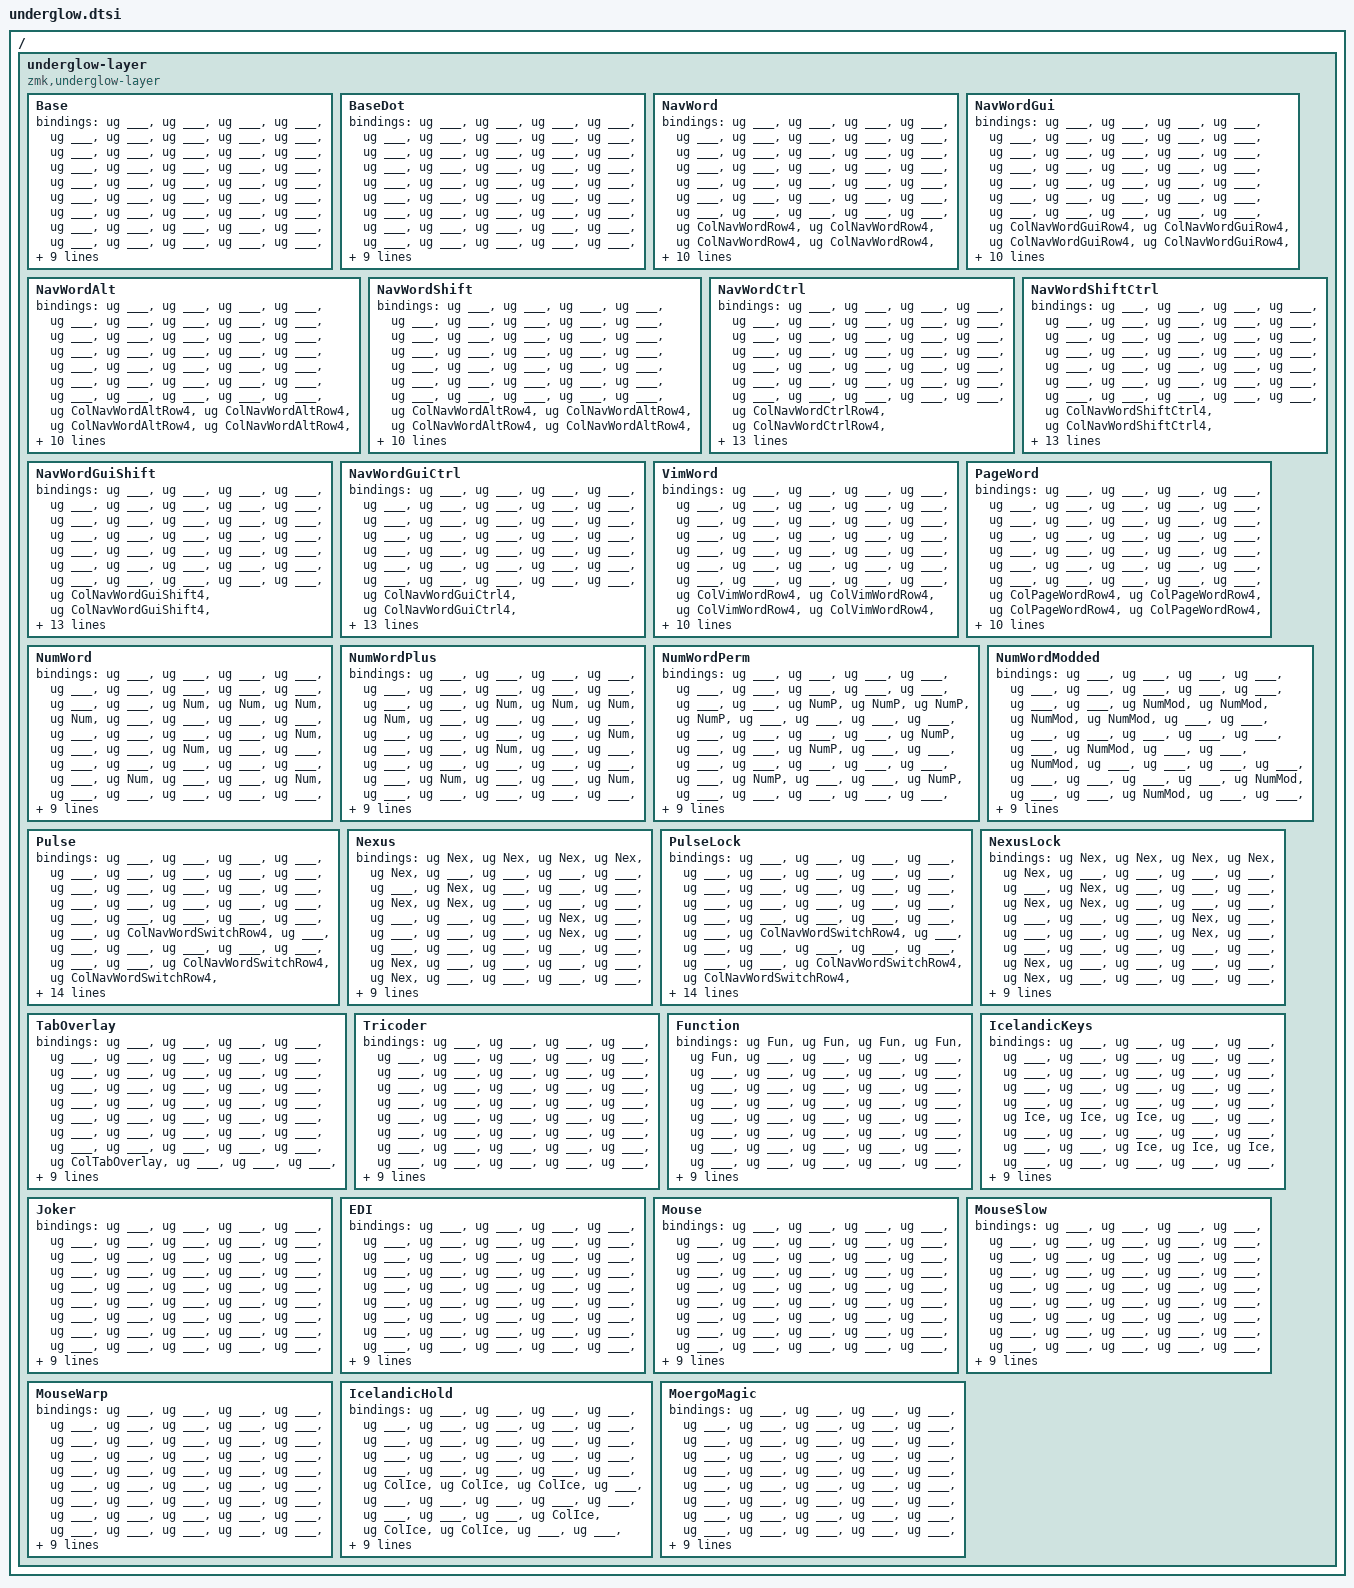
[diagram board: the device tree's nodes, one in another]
/ {
	#define GREEN 0x00ff00
	#define RED 0xff0000
	#define BLUE 0x0000ff
	#define TEAL 0x008080
	#define ORANGE 0xffa500
	#define YELLOW 0xffff00
	#define GOLD 0xffd700
	#define PURPLE 0x800080
	#define PINK 0xffc0cb
	#define WHITE 0xffffff
	#define ___ 0x000000
	
	// Added expanded palette (short names; comments clarify)
	#define CYAN 0x00ffff
	#define MAGENTA 0xff00ff
	#define AMBER 0xffbf00// warm amber
	#define CORAL 0xff7f50
	#define SALMON 0xfa8072
	#define ROSE 0xff007f// rose pink
	#define VIOLET 0xee82ee
	#define INDIGO 0x4b0082
	#define LAVENDER 0xe6e6fa
	#define SKY 0x87ceeb// sky blue
	#define DODGER 0x1e90ff// dodger blue
	#define NAVY 0x000080
	#define MAROON 0x800000
	#define OLIVE 0x808000
	#define BROWN 0x8b4513
	#define MINT 0x98ff98
	#define TURQ 0x40e0d0// turquoise
	#define CHART 0x7fff00// chartreuse
	#define STEEL 0x4682b4// steel blue
	#define SLATE 0x708090// slate gray
	
	// Semantic layer colors (edit here to change theme)
	#define ColMouse   CYAN
	#define ColSlow    STEEL
	#define ColWarp    MAGENTA
	#define ColFast    DODGER
	
	#define ColCtrl    TEAL
	#define ColAlt     BLUE
	#define ColShift   PINK
	#define ColGui     ORANGE
	
	// Navigation and indicators
	#define ColNav     WHITE
	#define ColLayer   WHITE// binary indicator bits (top-left)
	
	// Per-nav-layer row-4 accents
	#define ColNavWordRow4       0x33ccff
	#define ColNavWordGuiRow4    0xff9966
	#define ColNavWordAltRow4    0xcc99ff
	#define ColNavWordCtrlRow4   0x66ff99
	#define ColNavWordShiftCtrl4 0xff66cc
	#define ColNavWordGuiShift4  0xffcc66
	#define ColNavWordGuiCtrl4   0x99ffcc
	#define ColNavWordSwitchRow4 0x66ccff
	#define ColVimWordRow4       0x5cffb8
	#define ColPageWordRow4      0xff7f5c
	
	// Nexus row-1 accents
	#define Nex       0x5ad1ff
	#define ColNexusOverlayRow1 0xffb347
	#define ColTabOverlay    0x1ec912
	
	// Num row-2 accents (distinct from Nexus palette)
	/* #define Num     0xff4da6 */
	#define Num  0xedb228
	#define NumP  0x3cff9a
	#define NumMod   0x6f7bff
	
	// Mouse row-6 accents (distinct palette)
	#define Mou    0x4de2ff
	#define MouS    0x7dff4d
	#define MouW    0xff6fe0
	#define MouF    0xffe14d
	#define MouSw  0x9c7bff
	
	// Icelandic rows 3/4 accent
	#define Ice 0x3a7eea
	
	// Function row-3 accent (red, distinct from nav/num)
	#define Fun 0xff4444
	
	// Numeric layers
	#define ColNum     WHITE
	#define ColNumMod  GREEN
	#define ColNumPlus GOLD
	
	// Numeric shades (distinct hues per layer)
	// ColNum: vivid but not harsh, varied hues
	#define ColNum1  0x66ccff
	#define ColNum2  0x99aaff
	#define ColNum3  0xff99c2
	#define ColNum4  0x66ffcc
	#define ColNum5  0xffcc66
	#define ColNum6  0x66ffff
	#define ColNum7  0xcc99ff
	#define ColNum8  0xff99e6
	#define ColNum9  0x66ffd9
	#define ColNum0  0x80e5ff
	
	// ColNumMod: green/teal family, brighter tints
	#define ColNumMod1  0x2ee6a6
	#define ColNumMod2  0x00cc99
	#define ColNumMod3  0x66ff66
	#define ColNumMod4  0x99ff33
	#define ColNumMod5  0x00ff99
	#define ColNumMod6  0x33ffcc
	#define ColNumMod7  0x66e6b8
	#define ColNumMod8  0x00e673
	#define ColNumMod9  0x7fff7f
	#define ColNumMod0  0x33d17a
	
	// ColNumPlus: amber/orange family, distinct steps
	#define ColNumPlus1  0xffb84d
	#define ColNumPlus2  0xffc266
	#define ColNumPlus3  0xff9933
	#define ColNumPlus4  0xffd24d
	#define ColNumPlus5  0xffbf00
	#define ColNumPlus6  0xffcc33
	#define ColNumPlus7  0xffa64d
	#define ColNumPlus8  0xff8c1a
	#define ColNumPlus9  0xffb366
	#define ColNumPlus0  0xffa500
	
	// Page/Vim layers
	#define ColVim  WHITE
	#define ColPage WHITE
	
	// Other layers
	#define ColFun  PURPLE// function keys
	#define ColIce  SKY// icelandic layer
	#define ColSym1 AMBER// symbol layer
	#define ColSym2 GOLD// symbol layer
	#define ColSym3 CORAL// symbol layer
	
	/* &ug ___ sets the underglow LED to the specified color.  */
	/* &ug ___ sets the underglow color according to the CAPSLOCK state.  */
	/* &ug_nl and &ug_sl do the same for NumLock & ScrollLock respectively. */
	
	underglow-layer {
		compatible  = "zmk,underglow-layer";
		
		Base {
			bindings = <
			&ug ___ &ug ___ &ug ___   &ug ___   &ug ___                                                                    &ug ___ &ug ___ &ug ___ &ug ___ &ug ___
			&ug ___ &ug ___ &ug ___   &ug ___   &ug ___   &ug ___                                                  &ug ___ &ug ___ &ug ___ &ug ___ &ug ___ &ug ___
			&ug ___ &ug ___ &ug ___   &ug ___   &ug ___   &ug ___                                                  &ug ___ &ug ___ &ug ___ &ug ___ &ug ___ &ug ___
			&ug ___ &ug ___ &ug ___   &ug ___   &ug ___   &ug ___                                                  &ug ___ &ug ___ &ug ___ &ug ___ &ug ___ &ug ___
			&ug ___ &ug ___ &ug ___   &ug ___   &ug ___   &ug ___ &ug ___ &ug ___ &ug ___  &ug ___ &ug ___ &ug ___ &ug ___ &ug ___   &ug ___   &ug ___ &ug ___ &ug ___
			&ug ___ &ug ___ &ug_cl ___ WHITE   &ug ___   &ug ___           &ug ___ &ug ___ &ug ___ &ug ___ &ug ___ &ug ___ &ug ___ &ug ___ &ug ___ &ug ___ &ug ___
			>;
			layer-id = <BASE>;
		};
		
		BaseDot {
			bindings = <
			&ug ___ &ug ___ &ug ___   &ug ___   &ug ___                                                          &ug ___ &ug ___ &ug ___ &ug ___ &ug ___
			&ug ___ &ug ___ &ug ___     &ug ___   &ug ___   &ug ___                                          &ug ___ &ug ___ &ug ___ &ug ___ &ug ___ &ug ___
			&ug ___ &ug ___ &ug ___     &ug ___   &ug ___   &ug ___                                          &ug ___ &ug ___ &ug ___ &ug ___ &ug ___ &ug ___
			&ug ___ &ug ___ &ug ___     &ug ___   &ug ___   &ug ___                                          &ug ___ &ug ___ &ug ___ &ug ___ &ug ___ &ug ___
			&ug ___ &ug ___ &ug ___     &ug ___   &ug ___   &ug ___ &ug ___ &ug ___ &ug ___  &ug ___ &ug ___ &ug ___ &ug ___ &ug ___ &ug ___ &ug ___ &ug ___ &ug ___
			&ug ___ &ug ___ &ug ___     &ug ___   &ug ___           &ug ___ &ug ___ &ug ___ &ug ___ &ug ___ &ug ___ &ug ___ &ug ___ &ug ___ &ug ___ &ug ___
			>;
			layer-id = <BASE_DOT>;
		};

		NavWord {
			bindings = <
			&ug ___  &ug ___  &ug ___    &ug ___  &ug ___                                                                                &ug ___ &ug ___ &ug ___ &ug ___ &ug ___
			&ug ___  &ug ___  &ug ___    &ug ___  &ug ___  &ug ___                                                       &ug ___ &ug ___ &ug ___ &ug ___ &ug ___ &ug ___
			&ug ___  &ug ___  &ug ___    &ug ___  &ug ___  &ug ___                                                       &ug ___ &ug ___ &ug ___ &ug ___ &ug ___ &ug ___
			&ug ColNavWordRow4  &ug ColNavWordRow4  &ug ColNavWordRow4    &ug ColNavWordRow4  &ug ColNavWordRow4  &ug ColNavWordRow4                                                       &ug ___ &ug ___ &ug ___ &ug ___ &ug ___ &ug ___
			&ug ___  &ug ___  &ug ___    &ug ___   &ug ___  &ug ___  &ug ___  &ug ___  &ug ___     &ug ___  &ug ___  &ug ___    &ug ___    &ug ___     &ug ___     &ug ___     &ug ___  &ug ___
			&ug ___  &ug ___  &ug ___    &ug ___  &ug ___          &ug ___ &ug ___ &ug ___ &ug ___ &ug ___ &ug ___ &ug ___ &ug ___ &ug ___ &ug ___ &ug ___
			>;
			layer-id = <NAV_WORD>;
		};
		
		NavWordGui {
			bindings = <
			&ug ___  &ug ___  &ug ___    &ug ___  &ug ___                                                                         &ug ___ &ug ___ &ug ___ &ug ___ &ug ___
			&ug ___  &ug ___  &ug ___    &ug ___  &ug ___  &ug ___                                                              &ug ___ &ug ___ &ug ___ &ug ___ &ug ___ &ug ___
			&ug ___  &ug ___  &ug ___    &ug ___  &ug ___  &ug ___                                                              &ug ___ &ug ___ &ug ___ &ug ___ &ug ___ &ug ___
			&ug ColNavWordGuiRow4  &ug ColNavWordGuiRow4  &ug ColNavWordGuiRow4    &ug ColNavWordGuiRow4  &ug ColNavWordGuiRow4  &ug ColNavWordGuiRow4                                                       &ug ___ &ug ___ &ug ___ &ug ___ &ug ___ &ug ___
			&ug ___  &ug ___  &ug ___    &ug ___   &ug ___  &ug ___  &ug ___         &ug ___ &ug ___ &ug ___ &ug ___ &ug ___ &ug ___ &ug ___ &ug ___ &ug ___ &ug ___
			&ug ___  &ug ___  &ug ___    &ug ___  &ug ___          &ug ___ &ug ___ &ug ___ &ug ___ &ug ___ &ug ___ &ug ___ &ug ___ &ug ___ &ug ___ &ug ___
			>;
			layer-id = <NAV_WORD_GUI>;
		};
		
		NavWordAlt {
			bindings = <
			&ug ___ &ug ___ &ug ___    &ug ___  &ug ___                                                                         &ug ___ &ug ___ &ug ___ &ug ___ &ug ___
			&ug ___ &ug ___  &ug ___   &ug ___   &ug ___   &ug ___                                                 &ug ___ &ug ___ &ug ___ &ug ___ &ug ___ &ug ___
			&ug ___ &ug ___  &ug ___   &ug ___   &ug ___   &ug ___                                                 &ug ___ &ug ___ &ug ___ &ug ___ &ug ___ &ug ___
			&ug ColNavWordAltRow4 &ug ColNavWordAltRow4  &ug ColNavWordAltRow4   &ug ColNavWordAltRow4   &ug ColNavWordAltRow4   &ug ColNavWordAltRow4                                                 &ug ___ &ug ___ &ug ___ &ug ___ &ug ___ &ug ___
			&ug ___ &ug ___  &ug ___   &ug ___   &ug ___   &ug ___ &ug ___ &ug ___ &ug ___  &ug ___ &ug ___ &ug ___ &ug ___ &ug ___  &ug ___   &ug ___ &ug ___ &ug ___
			&ug ___ &ug ___  &ug ___   &ug ___   &ug ___           &ug ___ &ug ___ &ug ___ &ug ___ &ug ___ &ug ___ &ug ___ &ug ___ &ug ___ &ug ___ &ug ___
			>;
			layer-id = <NAV_WORD_ALT>;
		};
		
		NavWordShift {
			bindings = <
			&ug ___ &ug ___ &ug ___    &ug ___  &ug ___                                                                         &ug ___ &ug ___ &ug ___ &ug ___ &ug ___
			&ug ___ &ug ___  &ug ___   &ug ___   &ug ___   &ug ___                                                 &ug ___ &ug ___ &ug ___ &ug ___ &ug ___ &ug ___
			&ug ___ &ug ___  &ug ___   &ug ___   &ug ___   &ug ___                                                 &ug ___ &ug ___ &ug ___ &ug ___ &ug ___ &ug ___
			&ug ColNavWordAltRow4 &ug ColNavWordAltRow4  &ug ColNavWordAltRow4   &ug ColNavWordAltRow4   &ug ColNavWordAltRow4   &ug ColNavWordAltRow4                                                 &ug ___ &ug ___ &ug ___ &ug ___ &ug ___ &ug ___
			&ug ___ &ug ___  &ug ___   &ug ___   &ug ___   &ug ___ &ug ___ &ug ___ &ug ___  &ug ___ &ug ___ &ug ___ &ug ___ &ug ___  &ug ___   &ug ___ &ug ___ &ug ___
			&ug ___ &ug ___  &ug ___   &ug ___   &ug ___           &ug ___ &ug ___ &ug ___ &ug ___ &ug ___ &ug ___ &ug ___ &ug ___ &ug ___ &ug ___ &ug ___
			>;
			layer-id = <NAV_WORD_SHIFT>;
		};
		
		NavWordCtrl {
			bindings = <
			&ug ___  &ug ___  &ug ___    &ug ___  &ug ___                                                                         &ug ___ &ug ___ &ug ___ &ug ___ &ug ___
			&ug ___  &ug ___  &ug ___    &ug ___  &ug ___  &ug ___                                                       &ug ___ &ug ___ &ug ___ &ug ___ &ug ___ &ug ___
			&ug ___  &ug ___  &ug ___    &ug ___  &ug ___  &ug ___                                                       &ug ___ &ug ___ &ug ___ &ug ___ &ug ___ &ug ___
			&ug ColNavWordCtrlRow4  &ug ColNavWordCtrlRow4  &ug ColNavWordCtrlRow4    &ug ColNavWordCtrlRow4  &ug ColNavWordCtrlRow4  &ug ColNavWordCtrlRow4                                                       &ug ___ &ug ___ &ug ___ &ug ___ &ug ___ &ug ___
			&ug ___  &ug ___  &ug ___    &ug ___   &ug ___  &ug ___  &ug ___  &ug ___  &ug ___     &ug ___  &ug ___  &ug ___    &ug ___    &ug ___     &ug ___     &ug ___     &ug ___  &ug ___
			&ug ___  &ug ___  &ug ___    &ug ___  &ug ___          &ug ___ &ug ___ &ug ___ &ug ___ &ug ___ &ug ___ &ug ___ &ug ___ &ug ___ &ug ___ &ug ___
			>;
			layer-id = <NAV_WORD_CTRL>;
		};
		
		NavWordShiftCtrl {
			bindings = <
			&ug ___  &ug ___  &ug ___    &ug ___  &ug ___                                                                                &ug ___ &ug ___ &ug ___ &ug ___ &ug ___
			&ug ___  &ug ___  &ug ___    &ug ___  &ug ___  &ug ___                                                       &ug ___ &ug ___ &ug ___ &ug ___ &ug ___ &ug ___
			&ug ___  &ug ___  &ug ___    &ug ___  &ug ___  &ug ___                                                       &ug ___ &ug ___ &ug ___ &ug ___ &ug ___ &ug ___
			&ug ColNavWordShiftCtrl4  &ug ColNavWordShiftCtrl4  &ug ColNavWordShiftCtrl4    &ug ColNavWordShiftCtrl4  &ug ColNavWordShiftCtrl4  &ug ColNavWordShiftCtrl4                                                       &ug ___ &ug ___ &ug ___ &ug ___ &ug ___ &ug ___
			&ug ___  &ug ___  &ug ___    &ug ___   &ug ___  &ug ___  &ug ___  &ug ___  &ug ___     &ug ___  &ug ___  &ug ___    &ug ___    &ug ___     &ug ___     &ug ___     &ug ___  &ug ___
			&ug ___  &ug ___  &ug ___    &ug ___  &ug ___          &ug ___ &ug ___ &ug ___ &ug ___ &ug ___ &ug ___ &ug ___ &ug ___ &ug ___ &ug ___ &ug ___
			>;
			layer-id = <NAV_WORD_SHIFT_CTRL>;
		};
		
		NavWordGuiShift {
			bindings = <
			&ug ___  &ug ___  &ug ___    &ug ___  &ug ___                                                                         &ug ___ &ug ___ &ug ___ &ug ___ &ug ___
			&ug ___  &ug ___  &ug ___    &ug ___  &ug ___  &ug ___                                                              &ug ___ &ug ___ &ug ___ &ug ___ &ug ___ &ug ___
			&ug ___  &ug ___  &ug ___    &ug ___  &ug ___  &ug ___                                                              &ug ___ &ug ___ &ug ___ &ug ___ &ug ___ &ug ___
			&ug ColNavWordGuiShift4  &ug ColNavWordGuiShift4  &ug ColNavWordGuiShift4    &ug ColNavWordGuiShift4  &ug ColNavWordGuiShift4  &ug ColNavWordGuiShift4                                                       &ug ___ &ug ___ &ug ___ &ug ___ &ug ___ &ug ___
			&ug ___  &ug ___  &ug ___    &ug ___   &ug ___  &ug ___  &ug ___  &ug ___  &ug ___     &ug ___  &ug ___  &ug ___    &ug ___    &ug ___     &ug ___     &ug ___     &ug ___  &ug ___
			&ug ___  &ug ___  &ug ___    &ug ___  &ug ___          &ug ___ &ug ___ &ug ___ &ug ___ &ug ___ &ug ___ &ug ___ &ug ___ &ug ___ &ug ___ &ug ___
			>;
			layer-id = <NAV_WORD_SHIFT_GUI>;
		};
		
		NavWordGuiCtrl {
			bindings = <
			&ug ___  &ug ___  &ug ___    &ug ___  &ug ___                                                                         &ug ___ &ug ___ &ug ___ &ug ___ &ug ___
			&ug ___  &ug ___  &ug ___    &ug ___  &ug ___  &ug ___                                                              &ug ___ &ug ___ &ug ___ &ug ___ &ug ___ &ug ___
			&ug ___  &ug ___  &ug ___    &ug ___  &ug ___  &ug ___                                                              &ug ___ &ug ___ &ug ___ &ug ___ &ug ___ &ug ___
			&ug ColNavWordGuiCtrl4  &ug ColNavWordGuiCtrl4  &ug ColNavWordGuiCtrl4    &ug ColNavWordGuiCtrl4  &ug ColNavWordGuiCtrl4  &ug ColNavWordGuiCtrl4                                                       &ug ___ &ug ___ &ug ___ &ug ___ &ug ___ &ug ___
			&ug ___  &ug ___  &ug ___    &ug ___   &ug ___  &ug ___  &ug ___  &ug ___  &ug ___     &ug ___  &ug ___  &ug ___    &ug ___    &ug ___     &ug ___     &ug ___     &ug ___  &ug ___
			&ug ___  &ug ___  &ug ___    &ug ___  &ug ___          &ug ___ &ug ___ &ug ___ &ug ___ &ug ___ &ug ___ &ug ___ &ug ___ &ug ___ &ug ___ &ug ___
			>;
			layer-id = <NAV_WORD_CTRL_GUI>;
		};
		
		VimWord {
			bindings = <
			&ug ___ &ug ___ &ug ___   &ug ___   &ug ___                                                                &ug ___ &ug ___ &ug ___ &ug ___ &ug ___
			&ug ___  &ug ___ &ug ___   &ug ___     &ug ___   &ug ___                                              &ug ___ &ug ___ &ug ___ &ug ___ &ug ___ &ug ___
			&ug ___  &ug ___ &ug ___   &ug ___     &ug ___   &ug ___                                              &ug ___ &ug ___ &ug ___ &ug ___ &ug ___ &ug ___
			&ug ColVimWordRow4  &ug ColVimWordRow4 &ug ColVimWordRow4   &ug ColVimWordRow4     &ug ColVimWordRow4   &ug ColVimWordRow4                                              &ug ___ &ug ___ &ug ___ &ug ___ &ug ___ &ug ___
			&ug ___  &ug ___ &ug ___   &ug ___     &ug ___   &ug ___ &ug ___ &ug ___ &ug ___  &ug ___ &ug ___ &ug ___ &ug ___ &ug ___ &ug ___   &ug ___ &ug ___ &ug ___
			&ug ___  &ug ___ &ug ___   &ug ___     &ug ___           &ug ___ &ug ___ &ug ___ &ug ___ &ug ___ &ug ___ &ug ___ &ug ___ &ug ___ &ug ___ &ug ___
			>;
			layer-id = <VIM_WORD>;
		};
		
		PageWord {
			bindings = <
			&ug ___ &ug ___ &ug ___   &ug ___   &ug ___                                                                    &ug ___ &ug ___ &ug ___ &ug ___ &ug ___
			&ug ___ &ug ___  &ug ___   &ug ___     &ug ___   &ug ___                                              &ug ___ &ug ___ &ug ___ &ug ___ &ug ___ &ug ___
			&ug ___ &ug ___  &ug ___   &ug ___     &ug ___   &ug ___                                              &ug ___ &ug ___ &ug ___ &ug ___ &ug ___ &ug ___
			&ug ColPageWordRow4 &ug ColPageWordRow4  &ug ColPageWordRow4   &ug ColPageWordRow4     &ug ColPageWordRow4   &ug ColPageWordRow4                                              &ug ___ &ug ___ &ug ___ &ug ___ &ug ___ &ug ___
			&ug ___ &ug ___  &ug ___   &ug ___     &ug ___   &ug ___ &ug ___ &ug ___ &ug ___  &ug ___ &ug ___ &ug ___ &ug ___ &ug ___ &ug ___   &ug ___ &ug ___ &ug ___
			&ug ___ &ug ___  &ug ___   &ug ___     &ug ___           &ug ___ &ug ___ &ug ___ &ug ___ &ug ___ &ug ___ &ug ___ &ug ___ &ug ___ &ug ___ &ug ___
			>;
			layer-id = <PAGE_WORD>;
		};
		
		NumWord {
			bindings = <
			&ug ___ &ug ___ &ug ___ &ug ___ &ug ___                                                              &ug ___ &ug ___ &ug ___ &ug ___ &ug ___
			&ug ___ &ug Num &ug Num &ug Num &ug Num &ug ___                                                  &ug ___ &ug ___ &ug ___ &ug ___ &ug ___ &ug ___
			&ug ___ &ug Num &ug ___ &ug ___ &ug Num &ug ___                                                  &ug ___ &ug ___ &ug ___ &ug ___ &ug ___ &ug ___
			&ug ___ &ug Num &ug ___ &ug ___ &ug Num &ug ___                                                  &ug ___ &ug ___ &ug ___ &ug ___ &ug ___ &ug ___
			&ug ___ &ug Num &ug Num &ug Num &ug Num &ug ___ &ug ___ &ug ___ &ug ___  &ug ___ &ug ___ &ug ___ &ug ___ &ug ___   &ug ___   &ug ___ &ug ___ &ug ___
			&ug ___ &ug ___ &ug ___ &ug ___ &ug ___         &ug ___ &ug ___ &ug ___ &ug ___ &ug ___ &ug ___ &ug ___ &ug ___ &ug ___ &ug ___ &ug ___
			>;
			layer-id = <NUM_WORD>;
		};
		
		NumWordPlus {
			bindings = <
			&ug ___ &ug ___ &ug ___ &ug ___ &ug ___                                                              &ug ___ &ug ___ &ug ___ &ug ___ &ug ___
			&ug ___ &ug Num &ug Num &ug Num &ug Num &ug ___                                                  &ug ___ &ug ___ &ug ___ &ug ___ &ug ___ &ug ___
			&ug ___ &ug Num &ug ___ &ug ___ &ug Num &ug ___                                                  &ug ___ &ug ___ &ug ___ &ug ___ &ug ___ &ug ___
			&ug ___ &ug Num &ug ___ &ug ___ &ug Num &ug ___                                                  &ug ___ &ug ___ &ug ___ &ug ___ &ug ___ &ug ___
			&ug ___ &ug Num &ug Num &ug Num &ug Num &ug ___ &ug ___ &ug ___ &ug ___  &ug ___ &ug ___ &ug ___ &ug ___ &ug ___   &ug ___   &ug ___ &ug ___ &ug ___
			&ug ___ &ug ___ &ug ___ &ug ___ &ug ___         &ug ___ &ug ___ &ug ___ &ug ___ &ug ___ &ug ___ &ug ___ &ug ___ &ug ___ &ug ___ &ug ___
			>;
			layer-id = <NUM_WORD_PLUS>;
		};
		
		NumWordPerm {
			bindings = <
			&ug ___ &ug ___ &ug ___ &ug ___ &ug ___                                                              &ug ___ &ug ___ &ug ___ &ug ___ &ug ___
			&ug ___ &ug NumP &ug NumP &ug NumP &ug NumP &ug ___                                                  &ug ___ &ug ___ &ug ___ &ug ___ &ug ___ &ug ___
			&ug ___ &ug NumP &ug ___ &ug ___ &ug NumP &ug ___                                                  &ug ___ &ug ___ &ug ___ &ug ___ &ug ___ &ug ___
			&ug ___ &ug NumP &ug ___ &ug ___ &ug NumP &ug ___                                                  &ug ___ &ug ___ &ug ___ &ug ___ &ug ___ &ug ___
			&ug ___ &ug NumP &ug NumP &ug NumP &ug NumP &ug ___ &ug ___ &ug ___ &ug ___  &ug ___ &ug ___ &ug ___ &ug ___ &ug ___   &ug ___   &ug ___ &ug ___ &ug ___
			&ug ___ &ug ___ &ug ___ &ug ___ &ug ___         &ug ___ &ug ___ &ug ___ &ug ___ &ug ___ &ug ___ &ug ___ &ug ___ &ug ___ &ug ___ &ug ___
			>;
			layer-id = <NUM_WORD_PERMA>;
		};
		
		NumWordModded {
			bindings = <
			&ug ___ &ug ___ &ug ___ &ug ___ &ug ___                                                              &ug ___ &ug ___ &ug ___ &ug ___ &ug ___
			&ug ___ &ug NumMod &ug NumMod &ug NumMod &ug NumMod &ug ___                                                  &ug ___ &ug ___ &ug ___ &ug ___ &ug ___ &ug ___
			&ug ___ &ug NumMod &ug ___ &ug ___ &ug NumMod &ug ___                                                  &ug ___ &ug ___ &ug ___ &ug ___ &ug ___ &ug ___
			&ug ___ &ug NumMod &ug ___ &ug ___ &ug NumMod &ug ___                                                  &ug ___ &ug ___ &ug ___ &ug ___ &ug ___ &ug ___
			&ug ___ &ug NumMod &ug NumMod &ug NumMod &ug NumMod &ug ___ &ug ___ &ug ___ &ug ___  &ug ___ &ug ___ &ug ___ &ug ___ &ug ___   &ug ___   &ug ___ &ug ___ &ug ___
			&ug ___ &ug ___ &ug ___ &ug ___ &ug ___         &ug ___ &ug ___ &ug ___ &ug ___ &ug ___ &ug ___ &ug ___ &ug ___ &ug ___ &ug ___ &ug ___
			>;
			layer-id = <NUM_WORD_MODDED>;
		};
		
		Pulse {
			bindings = <
			&ug ___ &ug ___ &ug ___   &ug ___   &ug ___                                                                &ug ___ &ug ___ &ug ___ &ug ___ &ug ___
			&ug ___  &ug ___  &ug ___    &ug ___    &ug ___  &ug ___                                                       &ug ___ &ug ___ &ug ___ &ug ___ &ug ___ &ug ___
			&ug ___  &ug ___  &ug ___    &ug ColNavWordSwitchRow4    &ug ___  &ug ___                                                       &ug ___ &ug ___ &ug ___ &ug ___ &ug ___ &ug ___
			&ug ColNavWordSwitchRow4  &ug ColNavWordSwitchRow4  &ug ColNavWordSwitchRow4    &ug ColNavWordSwitchRow4    &ug ColNavWordSwitchRow4   &ug ColNavWordSwitchRow4                                                        &ug ___ &ug ___ &ug ___ &ug ___ &ug ___ &ug ___
			&ug ___  &ug ___  &ug ___    &ug ColNavWordSwitchRow4  &ug ___  &ug ___  &ug ___  &ug ___  &ug ___     &ug ___  &ug ___  &ug ___    &ug ___    &ug ___     &ug ___     &ug ___     &ug ___  &ug ___
			&ug ___  &ug ___  &ug ___    &ug ___    &ug ___          &ug ___ &ug ColNavWordSwitchRow4 &ug ___ &ug ___ &ug ___ &ug ___ &ug ___ &ug ___ &ug ___ &ug ___ &ug ___
			>;
			layer-id = <PULSE>;
		};
		
		Nexus {
			bindings = <
			&ug Nex &ug Nex &ug Nex   &ug Nex   &ug Nex                                                          &ug ___ &ug ___ &ug ___ &ug ___ &ug ___
			&ug Nex &ug ___  &ug ___     &ug ___     &ug Nex   &ug Nex                                            &ug ___ &ug ___ &ug ___ &ug ___ &ug ___ &ug ___
			&ug Nex &ug ___  &ug ___     &ug ___     &ug ___   &ug Nex                                            &ug ___ &ug ___ &ug ___ &ug ___ &ug ___ &ug ___
			&ug Nex &ug ___  &ug ___     &ug ___     &ug ___   &ug Nex                                            &ug ___ &ug ___ &ug ___ &ug ___ &ug ___ &ug ___
			&ug Nex &ug ___  &ug ___     &ug ___     &ug Nex   &ug Nex &ug ___ &ug ___ &ug ___  &ug ___ &ug ___ &ug ___ &ug ___ &ug ___ &ug ___ &ug ___ &ug ___ &ug ___
			&ug Nex &ug Nex  &ug Nex     &ug Nex     &ug Nex           &ug ___ &ug ___ &ug ___ &ug ___ &ug ___ &ug ___ &ug ___ &ug ___ &ug ___ &ug ___ &ug ___
			>;
			layer-id = <NEXUS>;
		};

		PulseLock {
			bindings = <
			&ug ___ &ug ___ &ug ___   &ug ___   &ug ___                                                                &ug ___ &ug ___ &ug ___ &ug ___ &ug ___
			&ug ___  &ug ___  &ug ___    &ug ___    &ug ___  &ug ___                                                       &ug ___ &ug ___ &ug ___ &ug ___ &ug ___ &ug ___
			&ug ___  &ug ___  &ug ___    &ug ColNavWordSwitchRow4    &ug ___  &ug ___                                                       &ug ___ &ug ___ &ug ___ &ug ___ &ug ___ &ug ___
			&ug ColNavWordSwitchRow4  &ug ColNavWordSwitchRow4  &ug ColNavWordSwitchRow4    &ug ColNavWordSwitchRow4    &ug ColNavWordSwitchRow4   &ug ColNavWordSwitchRow4                                                        &ug ___ &ug ___ &ug ___ &ug ___ &ug ___ &ug ___
			&ug ___  &ug ___  &ug ___    &ug ColNavWordSwitchRow4  &ug ___  &ug ___  &ug ___  &ug ___  &ug ___     &ug ___  &ug ___  &ug ___    &ug ___    &ug ___     &ug ___     &ug ___     &ug ___  &ug ___
			&ug ___  &ug ___  &ug ___    &ug ___    &ug ___          &ug ___ &ug ColNavWordSwitchRow4 &ug ___ &ug ___ &ug ___ &ug ___ &ug ___ &ug ___ &ug ___ &ug ___ &ug ___
			>;
			layer-id = <PULSE_LOCK>;
		};
		
		NexusLock {
			bindings = <
			&ug Nex &ug Nex &ug Nex   &ug Nex   &ug Nex                                                          &ug ___ &ug ___ &ug ___ &ug ___ &ug ___
			&ug Nex &ug ___  &ug ___     &ug ___     &ug Nex   &ug Nex                                            &ug ___ &ug ___ &ug ___ &ug ___ &ug ___ &ug ___
			&ug Nex &ug ___  &ug ___     &ug ___     &ug ___   &ug Nex                                            &ug ___ &ug ___ &ug ___ &ug ___ &ug ___ &ug ___
			&ug Nex &ug ___  &ug ___     &ug ___     &ug ___   &ug Nex                                            &ug ___ &ug ___ &ug ___ &ug ___ &ug ___ &ug ___
			&ug Nex &ug ___  &ug ___     &ug ___     &ug Nex   &ug Nex &ug ___ &ug ___ &ug ___  &ug ___ &ug ___ &ug ___ &ug ___ &ug ___ &ug ___ &ug ___ &ug ___ &ug ___
			&ug Nex &ug Nex  &ug Nex     &ug Nex     &ug Nex           &ug ___ &ug ___ &ug ___ &ug ___ &ug ___ &ug ___ &ug ___ &ug ___ &ug ___ &ug ___ &ug ___
			>;
			layer-id = <NEXUS_LOCK>;
		};

		TabOverlay {
			bindings = <
			&ug ___ &ug ___ &ug ___   &ug ___   &ug ___                                                           &ug ___ &ug ___ &ug ___ &ug ___ &ug ___
			&ug ___ &ug ___ &ug ___   &ug ___   &ug ___   &ug ___                                                 &ug ___ &ug ___ &ug ___ &ug ___ &ug ___ &ug ___
			&ug ___ &ug ___ &ug ___   &ug ___   &ug ___   &ug ___                                                 &ug ___ &ug ___ &ug ___ &ug ___ &ug ___ &ug ___
			&ug ___ &ug ___ &ug ___   &ug ___   &ug ___   &ug ColTabOverlay                                                 &ug ___ &ug ___ &ug ___ &ug ___ &ug ___ &ug ___
			&ug ___ &ug ___ &ug ___   &ug ___   &ug ___   &ug ___ &ug ___ &ug ___ &ug ___  &ug ___ &ug ___ &ug ___ &ug ___ &ug ___  &ug ___   &ug ___ &ug ___ &ug ___
			&ug ___ &ug ___ &ug ___   &ug ColTabOverlay   &ug ColTabOverlay           &ug ___ &ug ___ &ug ___ &ug ___ &ug ___ &ug ___ &ug ___ &ug ___ &ug ___ &ug ___ &ug ___
			>;
			layer-id = <TAB_OVERLAY>;
		};
		
		Tricoder {
			bindings = <
			&ug ___ &ug ___ &ug ___   &ug ___   &ug ___                                                           &ug ___ &ug ___ &ug ___ &ug ___ &ug ___
			&ug ___ &ug ___ &ug ___   &ug ___   &ug ___   &ug ___                                                 &ug ___ &ug ___ &ug ___ &ug ___ &ug ___ &ug ___
			&ug ___ &ug ___ &ug ___   &ug ___   &ug ___   &ug ___                                                 &ug ___ &ug ___ &ug ___ &ug ___ &ug ___ &ug ___
			&ug ___ &ug ___ &ug ___   &ug ___   &ug ___   &ug ___                                                 &ug ___ &ug ___ &ug ___ &ug ___ &ug ___ &ug ___
			&ug ___ &ug ___ &ug ___   &ug ___   &ug ___   &ug ColTabOverlay &ug ___ &ug ___ &ug ___  &ug ___ &ug ___ &ug ___ &ug ___ &ug ___  &ug ___   &ug ___ &ug ___ &ug ___
			&ug ___ &ug ___ &ug ___   &ug ___   &ug ___           &ug ColTabOverlay &ug ___ &ug ___ &ug ___ &ug ___ &ug ___ &ug ___ &ug ___ &ug ___ &ug ___ &ug ___
			>;
			layer-id = <TRICODER>;
		};
		
		Function {
			bindings = <
			&ug Fun &ug Fun  &ug Fun   &ug Fun   &ug Fun                                                         &ug ___ &ug ___ &ug ___ &ug ___ &ug ___
			&ug ___ &ug ___  &ug ___   &ug ___   &ug ___   &ug ___                                            &ug ___ &ug ___ &ug ___ &ug ___ &ug ___ &ug ___
	    &ug ___ &ug ___ &ug ___   &ug ___    &ug ___   &ug ___                                           &ug ___ &ug ___ &ug ___ &ug ___ &ug ___ &ug ___
			&ug ___ &ug ___  &ug ___   &ug ___   &ug ___   &ug ___                                            &ug ___ &ug ___ &ug ___ &ug ___ &ug ___ &ug ___
			&ug ___ &ug ___  &ug ___   &ug ___   &ug ___   &ug ___ &ug ___ &ug ___ &ug ___  &ug ___ &ug ___ &ug ___ &ug ___ &ug ___ &ug ___ &ug ___ &ug ___ &ug ___
			&ug ___ &ug ___  &ug ___   &ug ___   &ug ___           &ug ___ &ug ___ &ug ___ &ug ___ &ug ___ &ug ___ &ug ___ &ug ___ &ug ___ &ug ___ &ug ___
			>;
			layer-id = <FUNCTIONS>;
		};
		
		IcelandicKeys {
			bindings = <
			&ug ___ &ug ___ &ug ___   &ug ___   &ug ___                                                              &ug ___ &ug ___ &ug ___ &ug ___ &ug ___
			&ug ___  &ug ___  &ug ___    &ug ___   &ug ___   &ug ___                                        &ug ___ &ug ___ &ug ___ &ug ___ &ug ___ &ug ___
			&ug ___  &ug ___  &ug Ice    &ug Ice   &ug Ice   &ug ___                                        &ug ___ &ug ___ &ug ___ &ug ___ &ug ___ &ug ___
			&ug ___  &ug ___  &ug Ice    &ug Ice   &ug Ice   &ug ___                                        &ug ___ &ug ___ &ug ___ &ug ___ &ug ___ &ug ___
			&ug ___  &ug ___  &ug ___    &ug ___   &ug ___   &ug ___ &ug ___ &ug ___ &ug ___  &ug ___ &ug ___ &ug ___ &ug ___ &ug ___ &ug ___ &ug ___ &ug ___ &ug ___
			&ug ___  &ug ___  &ug ___    &ug ___   &ug ___           &ug ___ &ug ___ &ug ___ &ug ___ &ug ___ &ug ___ &ug ___ &ug ___ &ug ___ &ug ___ &ug ___
			>;
			layer-id = <ICE>;
		};
		
		Joker {
			bindings = <
			&ug ___ &ug ___ &ug ___   &ug ___   &ug ___                                                            &ug ___ &ug ___ &ug ___ &ug ___ &ug ___
			&ug ___  &ug ___ &ug ___     &ug ___   &ug ___   &ug ___                                            &ug ___ &ug ___ &ug ___ &ug ___ &ug ___ &ug ___
			&ug ___  &ug ___ &ug ___     &ug ___   &ug ___   &ug ___                                            &ug ___ &ug ___ &ug ___ &ug ___ &ug ___ &ug ___
			&ug ___  &ug ___ &ug ___     &ug ___   &ug ___   &ug ___                                            &ug ___ &ug ___ &ug ___ &ug ___ &ug ___ &ug ___
			&ug ___  &ug ___ &ug ___     &ug ___   &ug ___   &ug ___ &ug ___ &ug ___ &ug ___  &ug ___ &ug ___ &ug ___ &ug ___ &ug ___ &ug ___ &ug ___ &ug ___ &ug ___
			&ug ___  &ug ___ &ug ___     &ug ___   &ug ___           &ug ___ &ug ___ &ug ___ &ug ___ &ug ___ &ug ___ &ug ___ &ug ___ &ug ___ &ug ___ &ug ___
			>;
			layer-id = <JOKER>;
		};
		
		EDI {
			bindings = <
			&ug ___ &ug ___ &ug ___   &ug ___   &ug ___                                                          &ug ___ &ug ___ &ug ___ &ug ___ &ug ___
			&ug ___ &ug ___  &ug ___     &ug ___   &ug ___   &ug ___                                            &ug ___ &ug ___ &ug ___ &ug ___ &ug ___ &ug ___
			&ug ___ &ug ___  &ug ___     &ug ___   &ug ___   &ug ___                                            &ug ___ &ug ___ &ug ___ &ug ___ &ug ___ &ug ___
			&ug ___ &ug ___  &ug ___     &ug ___   &ug ___   &ug ___                                            &ug ___ &ug ___ &ug ___ &ug ___ &ug ___ &ug ___
			&ug ___ &ug ___  &ug ___     &ug ___   &ug ___   &ug ___ &ug ___ &ug ___ &ug ___  &ug ___ &ug ___ &ug ___ &ug ___ &ug ___ &ug ___ &ug ___ &ug ___ &ug ___
			&ug ___ &ug ___  &ug ___     &ug ___   &ug ___           &ug ___ &ug ___ &ug ___ &ug ___ &ug ___ &ug ___ &ug ___ &ug ___ &ug ___ &ug ___ &ug ___
			>;
			layer-id = <EDI_LAYER>;
		};
		
		Mouse {
			bindings = <
			&ug ___ &ug ___ &ug ___   &ug ___   &ug ___                                                              &ug ___ &ug ___ &ug ___ &ug ___ &ug ___
			&ug ___  &ug ___ &ug ___     &ug ___   &ug ___   &ug ___                                            &ug ___ &ug ___ &ug ___ &ug ___ &ug ___ &ug ___
			&ug ___  &ug ___ &ug ___     &ug ___   &ug ___   &ug ___                                            &ug ___ &ug ___ &ug ___ &ug ___ &ug ___ &ug ___
			&ug ___  &ug ___ &ug ___     &ug ___   &ug ___   &ug ___                                            &ug ___ &ug ___ &ug ___ &ug ___ &ug ___ &ug ___
			&ug ___  &ug ___ &ug ___     &ug ___   &ug ___   &ug ___ &ug Mou &ug Mou &ug Mou  &ug ___ &ug ___ &ug ___ &ug ___ &ug ___ &ug ___ &ug ___ &ug ___ &ug ___
			&ug ___  &ug ___ &ug ___     &ug ___   &ug ___           &ug Mou &ug Mou &ug Mou &ug ___ &ug ___ &ug ___ &ug ___ &ug ___ &ug ___ &ug ___ &ug ___
			>;
			layer-id = <MOUSE>;
		};
		
		MouseSlow {
			bindings = <
			&ug ___ &ug ___ &ug ___   &ug ___   &ug ___                                                            &ug ___ &ug ___ &ug ___ &ug ___ &ug ___
			&ug ___ &ug ___ &ug ___    &ug ___   &ug ___   &ug ___                                             &ug ___ &ug ___ &ug ___ &ug ___ &ug ___ &ug ___
			&ug ___ &ug ___ &ug ___    &ug ___   &ug ___   &ug ___                                            &ug ___ &ug ___ &ug ___ &ug ___ &ug ___ &ug ___
			&ug ___ &ug ___ &ug ___    &ug ___   &ug ___   &ug ___                                             &ug ___ &ug ___ &ug ___ &ug ___ &ug ___ &ug ___
			&ug ___ &ug ___ &ug ___    &ug ___   &ug ___   &ug ___ &ug MouS &ug MouS &ug MouS  &ug ___ &ug ___ &ug ___ &ug ___ &ug ___ &ug ___ &ug ___ &ug ___ &ug ___
			&ug ___ &ug ___ &ug ___    &ug ___   &ug ___           &ug MouS &ug MouS &ug MouS &ug ___ &ug ___ &ug ___ &ug ___ &ug ___ &ug ___ &ug ___ &ug ___
			>;
			layer-id = <MOUSE_SLOW>;
		};
		
		MouseWarp {
			bindings = <
			&ug ___ &ug ___ &ug ___   &ug ___   &ug ___                                                          &ug ___ &ug ___ &ug ___ &ug ___ &ug ___
			&ug ___  &ug ___ &ug ___    &ug ___   &ug ___   &ug ___                                            &ug ___ &ug ___ &ug ___ &ug ___ &ug ___ &ug ___
			&ug ___  &ug ___ &ug ___    &ug ___   &ug ___   &ug ___                                         &ug ___ &ug ___ &ug ___ &ug ___ &ug ___ &ug ___
			&ug ___  &ug ___ &ug ___    &ug ___   &ug ___   &ug ___                                         &ug ___ &ug ___ &ug ___ &ug ___ &ug ___ &ug ___
			&ug ___  &ug ___ &ug ___    &ug ___   &ug ___   &ug ___ &ug MouW &ug MouW &ug MouW  &ug ___ &ug ___ &ug ___ &ug ___ &ug ___ &ug ___ &ug ___ &ug ___ &ug ___
			&ug ___  &ug ___ &ug ___    &ug ___   &ug ___           &ug MouW &ug MouW &ug MouW &ug ___ &ug ___ &ug ___ &ug ___ &ug ___ &ug ___ &ug ___ &ug ___
			>;
			layer-id = <MOUSE_WARP>;
		};
		
		IcelandicHold {
			bindings = <
			&ug ___ &ug ___ &ug ___   &ug ___   &ug ___                                                                    &ug ___ &ug ___ &ug ___ &ug ___ &ug ___
			&ug ___ &ug ___  &ug ___    &ug ___   &ug ___   &ug ___                                          &ug ___ &ug ___ &ug ___ &ug ___ &ug ___ &ug ___
			&ug ___ &ug ___  &ug ColIce &ug ColIce &ug ColIce &ug ___                                       &ug ___ &ug ___ &ug ___ &ug ___ &ug ___ &ug ___
			&ug ___ &ug ___  &ug ColIce &ug ColIce &ug ColIce &ug ___                                       &ug ___ &ug ___ &ug ___ &ug ___ &ug ___ &ug ___
			&ug ___ &ug ___  &ug ___    &ug ___   &ug ___   &ug ___ &ug ___  &ug ___  &ug ___   &ug ___ &ug ___ &ug ___ &ug ___ &ug ___ &ug ___ &ug ___ &ug ___ &ug ___
			&ug ___ &ug ___  &ug ___    &ug ___   &ug ___           &ug ___  &ug ___  &ug ___  &ug ___ &ug ___ &ug ___ &ug ___ &ug ___ &ug ___ &ug ___ &ug ___
			>;
			layer-id = <ICE_HOLD>;
		};
		
		MoergoMagic {
			bindings = <
			&ug ___ &ug ___ &ug ___   &ug ___   &ug ___                                                          &ug ___ &ug ___ &ug ___ &ug ___ &ug ___
			&ug ___ &ug ___ &ug ___     &ug ___   &ug ___   &ug ___                                          &ug ___ &ug ___ &ug ___ &ug ___ &ug ___ &ug ___
			&ug ___ &ug ___ &ug ___     &ug ___   &ug ___   &ug ___                                          &ug ___ &ug ___ &ug ___ &ug ___ &ug ___ &ug ___
			&ug ___ &ug ___ &ug ___     &ug ___   &ug ___   &ug ___                                          &ug ___ &ug ___ &ug ___ &ug ___ &ug ___ &ug ___
			&ug ___ &ug ___ &ug ___     &ug ___   &ug ___   &ug ___ &ug ___ &ug ___ &ug ___  &ug ___ &ug ___ &ug ___ &ug ___ &ug ___ &ug ___ &ug ___ &ug ___ &ug ___
			&ug ___ &ug ___ &ug ___     &ug ___   &ug ___           &ug ___ &ug ___ &ug ___ &ug ___ &ug ___ &ug ___ &ug ___ &ug ___ &ug ___ &ug ___ &ug ___
			>;
			layer-id = <MAGIC>;
		};
		
	};
};
